# M470 register map
File version: 2.0.2.5
Registers are 32-bit, read-write, reset 0x0 unless marked. A register's access mark holds for its fields unless they carry their own. Offsets are from the block's base; [hi:lo] are bit positions; {n}, {i} and the like mark numbered series.

## OFD — Oscillation Frequency Detector (OFD)
Base 0x400F1000
0x00 CR1 reset 0x6 — OFD Control Register 1
  [7:0] OFDWEN
0x04 CR2 — OFD Control Register 2
  [7:0] OFDEN
0x08 MNPLLOFF — OFD Lower Detection Frequency Setting Register
  [8:0] OFDMNPLLOFF
0x0C MNPLLON — OFD Lower Detection Frequency Setting Register
  [8:0] OFDMNPLLON
0x10 MXPLLOFF — OFD Higher Detection Frequency Setting Register
  [8:0] OFDMXPLLOFF
0x14 MXPLLON — OFD Higher Detection Frequency Setting Register
  [8:0] OFDMXPLLON

## WD — Watchdog Timer (WD)
Base 0x400F2000
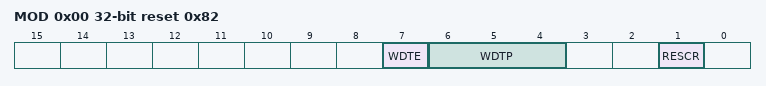
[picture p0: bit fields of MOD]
0x00 MOD reset 0x82 — WD Mode Register
  [7] WDTE, [6:4] WDTP, [1] RESCR
0x04 CR wo (reset mask 0xFFFFFF00) — WD Control Register
  [7:0] WDCR

## CG — Clock Generator (CG)
Base 0x400F3000
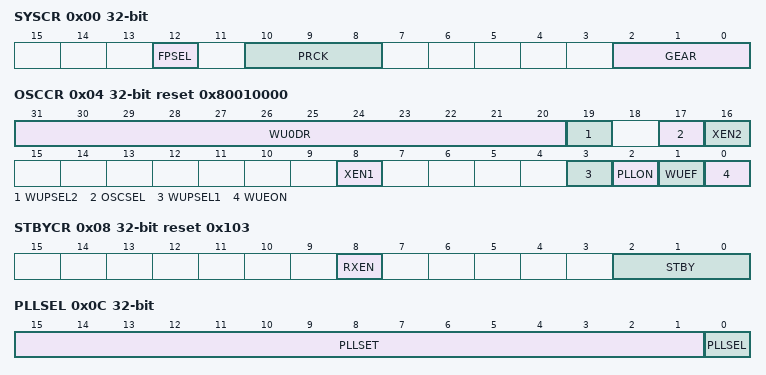
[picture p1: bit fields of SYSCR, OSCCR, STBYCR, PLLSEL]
0x00 SYSCR — System Control Register
  [12] FPSEL, [10:8] PRCK, [2:0] GEAR
0x04 OSCCR reset 0x80010000 — Oscillation Control Register
  [31:20] WU0DR, [19] WUPSEL2, [17] OSCSEL, [16] XEN2, [8] XEN1, [3] WUPSEL1, [2] PLLON, [1] WUEF ro, [0] WUEON wo
0x08 STBYCR reset 0x103 — Standby Control Register
  [8] RXEN, [2:0] STBY
0x0C PLLSEL — PLL Selection Register
  [15:1] PLLSET, [0] PLLSEL
0x14 ICRCG wo — CG Interrupt Request Clear Register
  [4:0] ICRCG
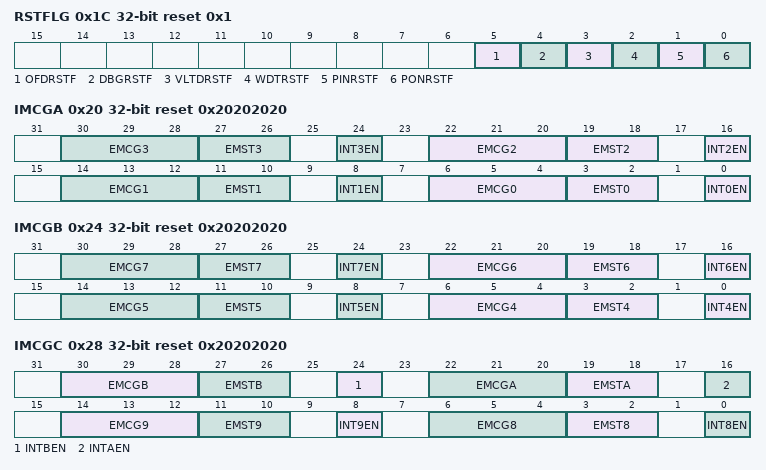
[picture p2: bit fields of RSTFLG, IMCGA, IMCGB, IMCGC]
0x1C RSTFLG reset 0x1 — Reset Flag Register
  [5] OFDRSTF, [4] DBGRSTF, [3] VLTDRSTF, [2] WDTRSTF, [1] PINRSTF, [0] PONRSTF
0x20 IMCGA reset 0x20202020 — CG Interrupt Mode Control Register A
  [8n+6:8n+4] EMCG{n} (n=0..3), [8n+3:8n+2] EMST{n} ro (n=0..3), [8n] INT{n}EN (n=0..3)
0x24 IMCGB reset 0x20202020 — CG Interrupt Mode Control Register B
  [8n-26:8n-28] EMCG{n} (n=4..7), [8n-29:8n-30] EMST{n} ro (n=4..7), [8n-32] INT{n}EN (n=4..7)
0x28 IMCGC reset 0x20202020 — CG Interrupt Mode Control Register C
  [30:28] EMCGB, [27:26] EMSTB ro, [24] INTBEN, [22:20] EMCGA, [19:18] EMSTA ro, [16] INTAEN, [14:12] EMCG9, [11:10] EMST9 ro, [8] INT9EN, [6:4] EMCG8, [3:2] EMST8 ro, [0] INT8EN
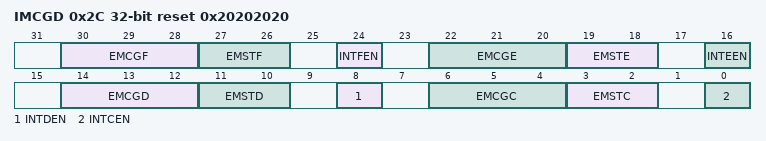
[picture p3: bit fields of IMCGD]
0x2C IMCGD reset 0x20202020 — CG Interrupt Mode Control Register D
  [30:28] EMCGF, [27:26] EMSTF ro, [24] INTFEN, [22:20] EMCGE, [19:18] EMSTE ro, [16] INTEEN, [14:12] EMCGD, [11:10] EMSTD ro, [8] INTDEN, [6:4] EMCGC, [3:2] EMSTC ro, [0] INTCEN

## TRMOSC — Internal High-speed Oscillation Adjustment
Base 0x400F3200
0x00 PRO — Protect Register
  [7:0] PROTECT
0x04 EN — Enable Register
  [0] TRIMEN
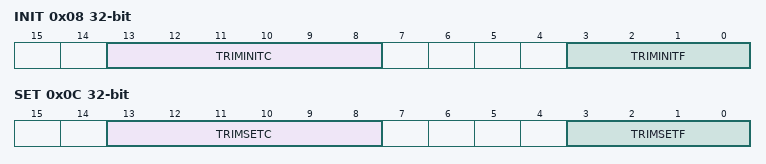
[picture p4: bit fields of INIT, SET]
0x08 INIT ro (reset mask 0xFFFFC0F0) — Initial Trimming Value Monitor Register
  [13:8] TRIMINITC, [3:0] TRIMINITF
0x0C SET — Timming Value Setting Register
  [13:8] TRIMSETC, [3:0] TRIMSETF

## NF — Digital Noize FilterClock Control
Base 0x400F3400
0x00 CKCR — Clcok Control
  [2:0] NFCKS
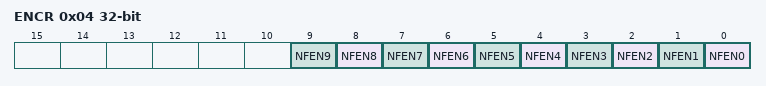
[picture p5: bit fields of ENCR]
0x04 ENCR — Enable Control
  [n] NFEN{n} (n=0..9)

## VD — Voltage Detection Control Circuit
Base 0x400F4000
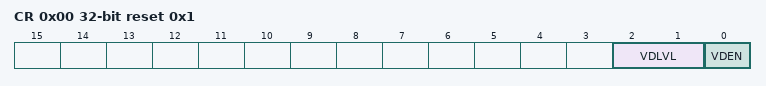
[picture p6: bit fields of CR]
0x00 CR reset 0x1 — VD Control Register
  [2:1] VDLVL, [0] VDEN

## PMD0 — Programmable Motor Driver (PMD)
Base 0x400F6000
Same registers: PMD1 0x400F6100
0x00 MDEN — PMD Enable Register
  [0] PWMEN
0x04 PORTMD — Port Output Mode Register
  [1:0] PORTMD
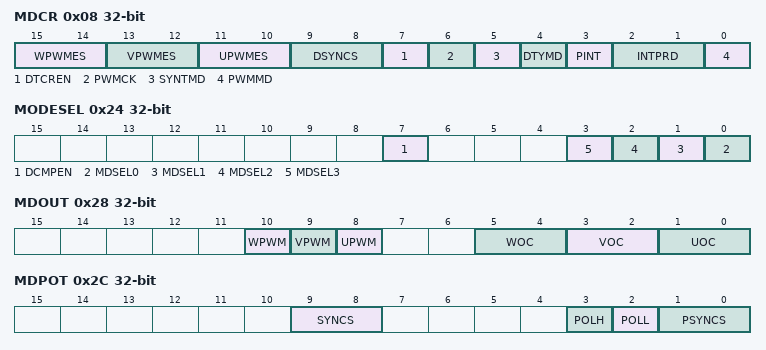
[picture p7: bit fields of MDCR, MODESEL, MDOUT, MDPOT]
0x08 MDCR — PMD Control Register
  [15:14] WPWMES, [13:12] VPWMES, [11:10] UPWMES, [9:8] DSYNCS, [7] DTCREN, [6] PWMCK, [5] SYNTMD, [4] DTYMD, [3] PINT, [2:1] INTPRD, [0] PWMMD
0x0C CNTSTA ro — PWM Counter Status Register
  [0] UPDWN
0x10 MDCNT ro — PWM Counter Register
  [15:0] MDCNT
0x14 MDPRD — PWM Period Register
  [15:0] MDPRD
0x18 CMPU — PWM Compare U Register
  [15:0] CMPU
0x1C CMPV — PWM Compare V Register
  [15:0] CMPV
0x20 CMPW — PWM Compare W Register
  [15:0] CMPW
0x24 MODESEL — Mode Select Register
  [7] DCMPEN, [n] MDSEL{n} (n=0..3)
0x28 MDOUT — PMD Conduction Control Register
  [10] WPWM, [9] VPWM, [8] UPWM, [5:4] WOC, [3:2] VOC, [1:0] UOC
0x2C MDPOT — PMD Output Setting Register
  [9:8] SYNCS, [3] POLH, [2] POLL, [1:0] PSYNCS
0x30 EMGREL wo — EMG Release Register
  [7:0] EMGREL
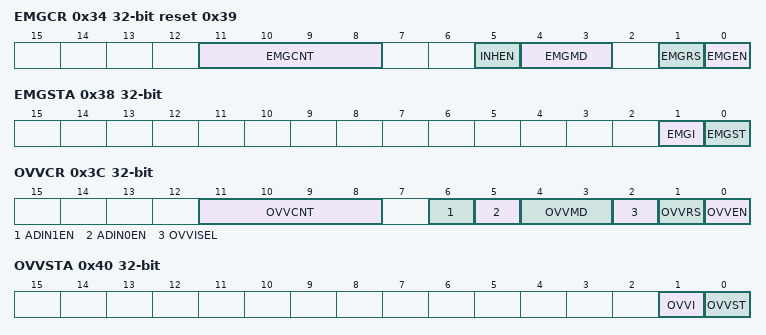
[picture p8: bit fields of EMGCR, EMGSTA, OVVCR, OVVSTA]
0x34 EMGCR reset 0x39 — EMG Control Register
  [11:8] EMGCNT, [5] INHEN wo, [4:3] EMGMD, [1] EMGRS wo, [0] EMGEN
0x38 EMGSTA ro (reset mask 0xFFFFFFFD) — EMG Status Register
  [1] EMGI, [0] EMGST
0x3C OVVCR — OVV Control Register
  [11:8] OVVCNT, [6] ADIN1EN, [5] ADIN0EN, [4:3] OVVMD, [2] OVVISEL, [1] OVVRS, [0] OVVEN
0x40 OVVSTA ro (reset mask 0xFFFFFFFD) — OVV Status Register
  [1] OVVI, [0] OVVST
0x44 DTR — Dead Time Register
  [7:0] DTR
{0x48+4i} TRGCMP{i} (i=0..3) — Trigger Compare Register {i}
  [15:0] TRGCMP{i}
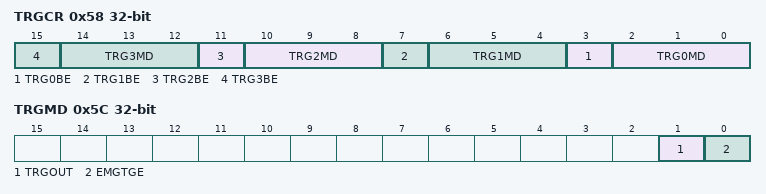
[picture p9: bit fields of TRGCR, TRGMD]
0x58 TRGCR — Trigger Control Register
  [4n+3] TRG{n}BE (n=0..3), [4n+2:4n] TRG{n}MD (n=0..3)
0x5C TRGMD — Trigger Output Mode Setting Register
  [1] TRGOUT, [0] EMGTGE
0x60 TRGSEL — Trigger Output Select Register
  [2:0] TRGSEL
0x64 TRGSYNCR — Trigger Update Timing Setting Register
  [1:0] TSYNCS
